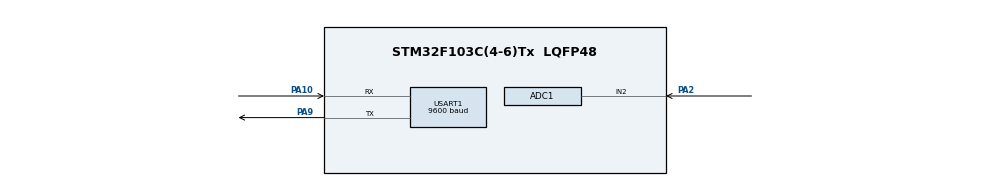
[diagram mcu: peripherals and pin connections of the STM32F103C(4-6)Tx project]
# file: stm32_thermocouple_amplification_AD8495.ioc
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ADC1.Channel-0\#ChannelRegularConversion=ADC_CHANNEL_2
ADC1.ContinuousConvMode=ENABLE
ADC1.NbrOfConversionFlag=1
ADC1.Rank-0\#ChannelRegularConversion=1
ADC1.SamplingTime-0\#ChannelRegularConversion=ADC_SAMPLETIME_1CYCLE_5
ADC1.master=1
Mcu.Family=STM32F1
Mcu.Name=STM32F103C(4-6)Tx
Mcu.Package=LQFP48
NVIC.PriorityGroup=NVIC_PRIORITYGROUP_4
PA10.Mode=Asynchronous
PA10.Signal=USART1_RX
PA2.Signal=ADCx_IN2
PA9.Mode=Asynchronous
PA9.Signal=USART1_TX
ProjectManager.HeapSize=0x200
ProjectManager.StackSize=0x400
ProjectManager.TargetToolchain=STM32CubeIDE
RCC.APB1Freq_Value=8000000
RCC.APB2Freq_Value=8000000
SH.ADCx_IN2.0=ADC1_IN2,IN2
USART1.BaudRate=9600
USART1.VirtualMode=VM_ASYNC
VP_SYS_VS_ND.Mode=No_Debug
board=custom

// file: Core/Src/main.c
/* USER CODE BEGIN Header */
/**
  ******************************************************************************
  * @file           : main.c
  * @brief          : Main program body
  ******************************************************************************
  * @attention
  *
  * Copyright (c) 2024 STMicroelectronics.
  * All rights reserved.
  *
  * This software is licensed under terms that can be found in the LICENSE file
  * in the root directory of this software component.
  * If no LICENSE file comes with this software, it is provided AS-IS.
  *
  ******************************************************************************
  */
/* USER CODE END Header */
#include "main.h"

/* USER CODE BEGIN Includes */
#include"stdio.h"
#include<string.h>
/* USER CODE END Includes */

ADC_HandleTypeDef hadc1;

UART_HandleTypeDef huart1;

/* USER CODE BEGIN PV */
int   val = 0; // Variable to store the value read
float TempC; // Temperature value in Celsius degree
float TempF; // Temperature value in Fahrenheit degree
float gain = (3.3/(4096-1)) ; // gain = STM23_Vref/(2^12-1) STM32 ADC 12bit resolution
float vref = 2.5; //  datasheet : Reference  value 2.5V for adjustment
float Output_Voltage= 0.005; // datasheet : 5 mV/°C for J type and K type
char  buffer[100];
/* USER CODE END PV */

void SystemClock_Config(void);
static void MX_GPIO_Init(void);
static void MX_ADC1_Init(void);
static void MX_USART1_UART_Init(void);

int main(void)
{

  /* MCU Configuration--------------------------------------------------------*/

  /* Reset of all peripherals, Initializes the Flash interface and the Systick. */
  HAL_Init();

  /* Configure the system clock */
  SystemClock_Config();

  /* Initialize all configured peripherals */
  MX_GPIO_Init();
  MX_ADC1_Init();
  MX_USART1_UART_Init();
  /* USER CODE BEGIN 2 */
  if(HAL_ADC_Start(&hadc1)!=HAL_OK)
  {
  Error_Handler();
  }
  /* USER CODE END 2 */

  /* Infinite loop */
  while (1)
  {

    /* USER CODE BEGIN 3 */
    while(HAL_ADC_PollForConversion(&hadc1, HAL_MAX_DELAY)!=HAL_OK)
    {
    Error_Handler();
    }
    val = HAL_ADC_GetValue(&hadc1);                         // Read the input from ADC
    TempC = (( (float)(val) * gain)-vref)/ Output_Voltage;  // -ref Convert ADC value to Celsius degree
    TempF = (TempC * 1.8) + 32.0;
    sprintf(buffer, "Temperature: %.2f Degrees Celsius, %.2f  Degrees Fahrenheit\r\n", TempC,TempF);
    HAL_UART_Transmit(&huart1, (uint8_t *)buffer, strlen(buffer), HAL_MAX_DELAY);
    HAL_Delay(500);
  }
  /* USER CODE END 3 */
}

void SystemClock_Config(void)
{
  RCC_OscInitTypeDef RCC_OscInitStruct = {0};
  RCC_ClkInitTypeDef RCC_ClkInitStruct = {0};
  RCC_PeriphCLKInitTypeDef PeriphClkInit = {0};

  /** Initializes the RCC Oscillators according to the specified parameters
  * in the RCC_OscInitTypeDef structure.
  */
  RCC_OscInitStruct.OscillatorType = RCC_OSCILLATORTYPE_HSI;
  RCC_OscInitStruct.HSIState = RCC_HSI_ON;
  RCC_OscInitStruct.HSICalibrationValue = RCC_HSICALIBRATION_DEFAULT;
  RCC_OscInitStruct.PLL.PLLState = RCC_PLL_NONE;
  if (HAL_RCC_OscConfig(&RCC_OscInitStruct) != HAL_OK)
  {
    Error_Handler();
  }

  /** Initializes the CPU, AHB and APB buses clocks
  */
  RCC_ClkInitStruct.ClockType = RCC_CLOCKTYPE_HCLK|RCC_CLOCKTYPE_SYSCLK
                              |RCC_CLOCKTYPE_PCLK1|RCC_CLOCKTYPE_PCLK2;
  RCC_ClkInitStruct.SYSCLKSource = RCC_SYSCLKSOURCE_HSI;
  RCC_ClkInitStruct.AHBCLKDivider = RCC_SYSCLK_DIV1;
  RCC_ClkInitStruct.APB1CLKDivider = RCC_HCLK_DIV1;
  RCC_ClkInitStruct.APB2CLKDivider = RCC_HCLK_DIV1;

  if (HAL_RCC_ClockConfig(&RCC_ClkInitStruct, FLASH_LATENCY_0) != HAL_OK)
  {
    Error_Handler();
  }
  PeriphClkInit.PeriphClockSelection = RCC_PERIPHCLK_ADC;
  PeriphClkInit.AdcClockSelection = RCC_ADCPCLK2_DIV2;
  if (HAL_RCCEx_PeriphCLKConfig(&PeriphClkInit) != HAL_OK)
  {
    Error_Handler();
  }
}

static void MX_ADC1_Init(void)
{

  ADC_ChannelConfTypeDef sConfig = {0};

  /** Common config
  */
  hadc1.Instance = ADC1;
  hadc1.Init.ScanConvMode = ADC_SCAN_DISABLE;
  hadc1.Init.ContinuousConvMode = ENABLE;
  hadc1.Init.DiscontinuousConvMode = DISABLE;
  hadc1.Init.ExternalTrigConv = ADC_SOFTWARE_START;
  hadc1.Init.DataAlign = ADC_DATAALIGN_RIGHT;
  hadc1.Init.NbrOfConversion = 1;
  if (HAL_ADC_Init(&hadc1) != HAL_OK)
  {
    Error_Handler();
  }

  /** Configure Regular Channel
  */
  sConfig.Channel = ADC_CHANNEL_2;
  sConfig.Rank = ADC_REGULAR_RANK_1;
  sConfig.SamplingTime = ADC_SAMPLETIME_1CYCLE_5;
  if (HAL_ADC_ConfigChannel(&hadc1, &sConfig) != HAL_OK)
  {
    Error_Handler();
  }

}

static void MX_USART1_UART_Init(void)
{

  huart1.Instance = USART1;
  huart1.Init.BaudRate = 9600;
  huart1.Init.WordLength = UART_WORDLENGTH_8B;
  huart1.Init.StopBits = UART_STOPBITS_1;
  huart1.Init.Parity = UART_PARITY_NONE;
  huart1.Init.Mode = UART_MODE_TX_RX;
  huart1.Init.HwFlowCtl = UART_HWCONTROL_NONE;
  huart1.Init.OverSampling = UART_OVERSAMPLING_16;
  if (HAL_UART_Init(&huart1) != HAL_OK)
  {
    Error_Handler();
  }

}

static void MX_GPIO_Init(void)
{

  /* GPIO Ports Clock Enable */
  __HAL_RCC_GPIOA_CLK_ENABLE();

}

void Error_Handler(void)
{
  __disable_irq();
  while (1)
  {
  }
}
